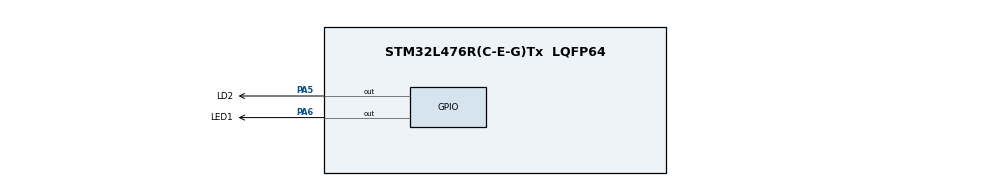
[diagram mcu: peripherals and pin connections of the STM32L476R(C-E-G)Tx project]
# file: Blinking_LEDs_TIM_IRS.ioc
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Mcu.Family=STM32L4
Mcu.Name=STM32L476R(C-E-G)Tx
Mcu.Package=LQFP64
NVIC.PriorityGroup=NVIC_PRIORITYGROUP_4
NVIC.TIM3_IRQn=true\:10\:0\:true\:false\:true\:true\:true\:true
PA13\ (JTMS-SWDIO).Mode=Serial_Wire
PA13\ (JTMS-SWDIO).Signal=SYS_JTMS-SWDIO
PA14\ (JTCK-SWCLK).Mode=Serial_Wire
PA14\ (JTCK-SWCLK).Signal=SYS_JTCK-SWCLK
PA5.GPIO_Label=LD2
PA5.Signal=GPIO_Output
PA6.GPIO_Label=LED1
PA6.Signal=GPIO_Output
ProjectManager.HeapSize=0x200
ProjectManager.StackSize=0x400
ProjectManager.TargetToolchain=STM32CubeIDE
RCC.HSE_VALUE=8000000
RCC.HSI_VALUE=16000000
RCC.LSE_VALUE=32768
RCC.MSI_VALUE=4000000
RCC.VCOOutputFreq_Value=32000000
TIM3.Channel-Output\ Compare1\ No\ Output=TIM_CHANNEL_1
TIM3.Period=19999
TIM3.Prescaler=3999
TIM3.Pulse-Output\ Compare1\ No\ Output=500
VP_TIM3_VS_ClockSourceINT.Mode=Internal
VP_TIM3_VS_no_output1.Mode=Output Compare1 No Output
board=custom

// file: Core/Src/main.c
/* USER CODE BEGIN Header */
/**
  ******************************************************************************
  * @file           : main.c
  * @brief          : Main program body
  ******************************************************************************
  * @attention
  *
  * Copyright (c) 2025 STMicroelectronics.
  * All rights reserved.
  *
  * This software is licensed under terms that can be found in the LICENSE file
  * in the root directory of this software component.
  * If no LICENSE file comes with this software, it is provided AS-IS.
  *
  ******************************************************************************
  */
/* USER CODE END Header */
#include "main.h"

TIM_HandleTypeDef htim3;

void SystemClock_Config(void);
static void MX_GPIO_Init(void);
static void MX_TIM3_Init(void);

/* USER CODE BEGIN 0 */
void HAL_TIM_PeriodElapsedCallback(TIM_HandleTypeDef *htim)
{
	if(htim == &htim3)
	{
		HAL_GPIO_TogglePin(LD2_GPIO_Port, LD2_Pin);

		HAL_GPIO_WritePin(LED1_GPIO_Port, LED1_Pin, GPIO_PIN_SET);
	}
}

void HAL_TIM_OC_DelayElapsedCallback(TIM_HandleTypeDef *htim)
{
	if(htim == &htim3)
	{
		if(HAL_TIM_GetActiveChannel(&htim3) == HAL_TIM_ACTIVE_CHANNEL_1){
			HAL_GPIO_WritePin(LED1_GPIO_Port, LED1_Pin, GPIO_PIN_RESET);
		}
	}
}
/* USER CODE END 0 */

int main(void)
{

  /* MCU Configuration--------------------------------------------------------*/

  /* Reset of all peripherals, Initializes the Flash interface and the Systick. */
  HAL_Init();

  /* Configure the system clock */
  SystemClock_Config();

  /* Initialize all configured peripherals */
  MX_GPIO_Init();
  MX_TIM3_Init();
  /* USER CODE BEGIN 2 */
  HAL_TIM_Base_Start_IT(&htim3);

  HAL_TIM_OC_Start_IT(&htim3, TIM_CHANNEL_1);
  /* USER CODE END 2 */

  /* Infinite loop */
  while (1)
  {

  }
}

void SystemClock_Config(void)
{
  RCC_OscInitTypeDef RCC_OscInitStruct = {0};
  RCC_ClkInitTypeDef RCC_ClkInitStruct = {0};

  /** Configure the main internal regulator output voltage
  */
  if (HAL_PWREx_ControlVoltageScaling(PWR_REGULATOR_VOLTAGE_SCALE1) != HAL_OK)
  {
    Error_Handler();
  }

  /** Initializes the RCC Oscillators according to the specified parameters
  * in the RCC_OscInitTypeDef structure.
  */
  RCC_OscInitStruct.OscillatorType = RCC_OSCILLATORTYPE_MSI;
  RCC_OscInitStruct.MSIState = RCC_MSI_ON;
  RCC_OscInitStruct.MSICalibrationValue = 0;
  RCC_OscInitStruct.MSIClockRange = RCC_MSIRANGE_6;
  RCC_OscInitStruct.PLL.PLLState = RCC_PLL_NONE;
  if (HAL_RCC_OscConfig(&RCC_OscInitStruct) != HAL_OK)
  {
    Error_Handler();
  }

  /** Initializes the CPU, AHB and APB buses clocks
  */
  RCC_ClkInitStruct.ClockType = RCC_CLOCKTYPE_HCLK|RCC_CLOCKTYPE_SYSCLK
                              |RCC_CLOCKTYPE_PCLK1|RCC_CLOCKTYPE_PCLK2;
  RCC_ClkInitStruct.SYSCLKSource = RCC_SYSCLKSOURCE_MSI;
  RCC_ClkInitStruct.AHBCLKDivider = RCC_SYSCLK_DIV1;
  RCC_ClkInitStruct.APB1CLKDivider = RCC_HCLK_DIV1;
  RCC_ClkInitStruct.APB2CLKDivider = RCC_HCLK_DIV1;

  if (HAL_RCC_ClockConfig(&RCC_ClkInitStruct, FLASH_LATENCY_0) != HAL_OK)
  {
    Error_Handler();
  }
}

static void MX_TIM3_Init(void)
{

  TIM_ClockConfigTypeDef sClockSourceConfig = {0};
  TIM_MasterConfigTypeDef sMasterConfig = {0};
  TIM_OC_InitTypeDef sConfigOC = {0};

  htim3.Instance = TIM3;
  htim3.Init.Prescaler = 3999;
  htim3.Init.CounterMode = TIM_COUNTERMODE_UP;
  htim3.Init.Period = 19999;
  htim3.Init.ClockDivision = TIM_CLOCKDIVISION_DIV1;
  htim3.Init.AutoReloadPreload = TIM_AUTORELOAD_PRELOAD_DISABLE;
  if (HAL_TIM_Base_Init(&htim3) != HAL_OK)
  {
    Error_Handler();
  }
  sClockSourceConfig.ClockSource = TIM_CLOCKSOURCE_INTERNAL;
  if (HAL_TIM_ConfigClockSource(&htim3, &sClockSourceConfig) != HAL_OK)
  {
    Error_Handler();
  }
  if (HAL_TIM_OC_Init(&htim3) != HAL_OK)
  {
    Error_Handler();
  }
  sMasterConfig.MasterOutputTrigger = TIM_TRGO_RESET;
  sMasterConfig.MasterSlaveMode = TIM_MASTERSLAVEMODE_DISABLE;
  if (HAL_TIMEx_MasterConfigSynchronization(&htim3, &sMasterConfig) != HAL_OK)
  {
    Error_Handler();
  }
  sConfigOC.OCMode = TIM_OCMODE_TIMING;
  sConfigOC.Pulse = 500;
  sConfigOC.OCPolarity = TIM_OCPOLARITY_HIGH;
  sConfigOC.OCFastMode = TIM_OCFAST_DISABLE;
  if (HAL_TIM_OC_ConfigChannel(&htim3, &sConfigOC, TIM_CHANNEL_1) != HAL_OK)
  {
    Error_Handler();
  }

}

static void MX_GPIO_Init(void)
{
  GPIO_InitTypeDef GPIO_InitStruct = {0};

  /* GPIO Ports Clock Enable */
  __HAL_RCC_GPIOA_CLK_ENABLE();

  /*Configure GPIO pin Output Level */
  HAL_GPIO_WritePin(GPIOA, LD2_Pin|LED1_Pin, GPIO_PIN_RESET);

  /*Configure GPIO pins : LD2_Pin LED1_Pin */
  GPIO_InitStruct.Pin = LD2_Pin|LED1_Pin;
  GPIO_InitStruct.Mode = GPIO_MODE_OUTPUT_PP;
  GPIO_InitStruct.Pull = GPIO_NOPULL;
  GPIO_InitStruct.Speed = GPIO_SPEED_FREQ_LOW;
  HAL_GPIO_Init(GPIOA, &GPIO_InitStruct);

}

void Error_Handler(void)
{
  __disable_irq();
  while (1)
  {
  }
}
